# AE350_4GB register map
Vendor: Andes Technology; Series: AE350; File version: 1.3.0
Registers are 32-bit, read-write, reset 0x0 unless marked. A register's access mark holds for its fields unless they carry their own. Offsets are from the block's base; [hi:lo] are bit positions; {n}, {i} and the like mark numbered series.

## PLIC_NumIntTarget_Version — Platform-Level Interrupt Controller
Base 0xE4000000
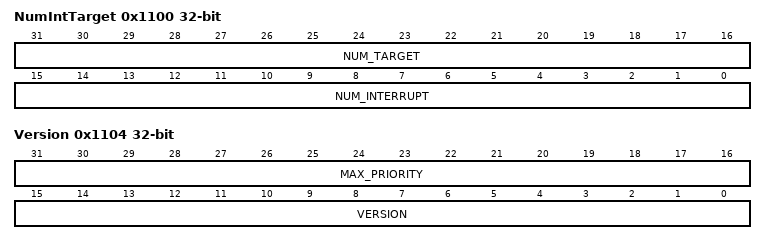
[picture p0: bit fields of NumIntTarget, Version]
0x1100 NumIntTarget — Number of Interrupt and Target Configuration Register
  [31:16] NUM_TARGET ro — Number of supported target
  [15:0] NUM_INTERRUPT ro — Number of supported interrupt source
0x1104 Version — Version & Maximum Priority Configuration Register
  [31:16] MAX_PRIORITY ro — The maximum priority supported
  [15:0] VERSION ro — The version of the PLIC design

## PLIC_Target0_3IntEnableBits — Platform-Level Interrupt Controller
Base 0xE4000000
{0x2000+4i} Target0IntEnableBits_{i} (i=0..31) — Target 0 interrupt enable bits
  [?] FIELD_1
{0x2080+4i} Target1IntEnableBits_{i} (i=0..31) — Target 1 interrupt enable bits
  [?] FIELD_1
{0x2100+4i} Target2IntEnableBits_{i} (i=0..31) — Target 2 interrupt enable bits
  [?] FIELD_1
{0x2180+4i} Target3IntEnableBits_{i} (i=0..31) — Target 3 interrupt enable bits
  [?] FIELD_1

## PLIC_Target4_7IntEnableBits — Platform-Level Interrupt Controller
Base 0xE4000000
{0x2200+4i} Target4IntEnableBits_{i} (i=0..31) — Target 4 interrupt enable bits
  [?] FIELD_1
{0x2280+4i} Target5IntEnableBits_{i} (i=0..31) — Target 5 interrupt enable bits
  [?] FIELD_1
{0x2300+4i} Target6IntEnableBits_{i} (i=0..31) — Target 6 interrupt enable bits
  [?] FIELD_1
{0x2380+4i} Target7IntEnableBits_{i} (i=0..31) — Target 7 interrupt enable bits
  [?] FIELD_1

## PLIC_Target8_11IntEnableBits — Platform-Level Interrupt Controller
Base 0xE4000000
{0x2400+4i} Target8IntEnableBits_{i} (i=0..31) — Target 8 interrupt enable bits
  [?] FIELD_1
{0x2480+4i} Target9IntEnableBits_{i} (i=0..31) — Target 9 interrupt enable bits
  [?] FIELD_1
{0x2500+4i} Target10IntEnableBits_{i} (i=0..31) — Target 10 interrupt enable bits
  [?] FIELD_1
{0x2580+4i} Target11IntEnableBits_{i} (i=0..31) — Target 11 interrupt enable bits
  [?] FIELD_1

## PLIC_Target12_15IntEnableBits — Platform-Level Interrupt Controller
Base 0xE4000000
{0x2600+4i} Target12IntEnableBits_{i} (i=0..31) — Target 12 interrupt enable bits
  [?] FIELD_1
{0x2680+4i} Target13IntEnableBits_{i} (i=0..31) — Target 13 interrupt enable bits
  [?] FIELD_1
{0x2700+4i} Target14IntEnableBits_{i} (i=0..31) — Target 14 interrupt enable bits
  [?] FIELD_1
{0x2780+4i} Target15IntEnableBits_{i} (i=0..31) — Target 15 interrupt enable bits
  [?] FIELD_1

## PLIC_Target0_3 — Platform-Level Interrupt Controller
Base 0xE4000000
{0x200000+0x1000*i} Target{i}PriorityThreshold (i=0..3)
  [?] FIELD_1
{0x200004+0x1000*i} Target{i}ClaimComplete (i=0..3) — Target {i} Claim and Complete
  [9:0] INTERRUPT_ID — Interrupt source ID
{0x200400+4i} Target0PreemptedPriorityStack_{i} (i=0..7) — Target 0 preempted priority stack
  [?] FIELD_1
{0x201400+4i} Target1PreemptedPriorityStack_{i} (i=0..7) — Target 1 preempted priority stack
  [?] FIELD_1
{0x202400+4i} Target2PreemptedPriorityStack_{i} (i=0..7) — Target 2 preempted priority stack
  [?] FIELD_1
{0x203400+4i} Target3PreemptedPriorityStack_{i} (i=0..7) — Target 3 preempted priority stack
  [?] FIELD_1

## PLIC_Target4_7 — Platform-Level Interrupt Controller
Base 0xE4000000
{0x200000+0x1000*i} Target{i}PriorityThreshold (i=4..7)
  [?] FIELD_1
{0x200004+0x1000*i} Target{i}ClaimComplete (i=4..7) — Target {i} Claim and Complete
  [9:0] INTERRUPT_ID — Interrupt source ID
{0x204400+4i} Target4PreemptedPriorityStack_{i} (i=0..7) — Target 4 preempted priority stack
  [?] FIELD_1
{0x205400+4i} Target5PreemptedPriorityStack_{i} (i=0..7) — Target 5 preempted priority stack
  [?] FIELD_1
{0x206400+4i} Target6PreemptedPriorityStack_{i} (i=0..7) — Target 6 preempted priority stack
  [?] FIELD_1
{0x207400+4i} Target7PreemptedPriorityStack_{i} (i=0..7) — Target 7 preempted priority stack
  [?] FIELD_1
